# STM32U083 register map
File version: 0.2
CPU: CM0+ r0p1, little endian, MPU, no FPU, 4 interrupt priority bits
Registers are 32-bit, read-write, reset 0x0 unless marked. A register's access mark holds for its fields unless they carry their own. Offsets are from the block's base; [hi:lo] are bit positions.

## DAC — DAC address block description
Base 0x40007400
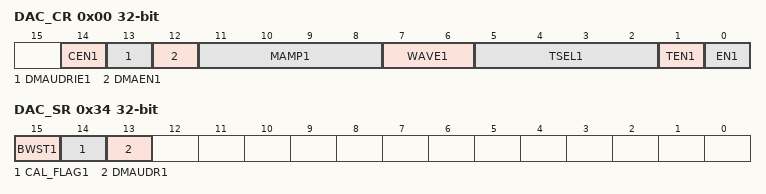
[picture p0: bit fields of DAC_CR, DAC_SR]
0x00 DAC_CR — DAC control register
  [14] CEN1 — DAC channel1 calibration enable This bit is set and cleared by software to enable/disable DAC channel1 calibration, it can be written only if bit EN11=10 into DAC_CR (the calibration mode can be entered/exit only when the DAC channel is disabled) Otherwise, the write operation is ignored.
    0=DAC channel1 in Normal operating mode; 1=DAC channel1 in calibration mode
  [13] DMAUDRIE1 — DAC channel1 DMA Underrun Interrupt enable This bit is set and cleared by software.
    0=DAC channel1 DMA Underrun Interrupt disabled; 1=DAC channel1 DMA Underrun Interrupt enabled
  [12] DMAEN1 — DAC channel1 DMA enable This bit is set and cleared by software.
    0=DAC channel1 DMA mode disabled; 1=DAC channel1 DMA mode enabled
  [11:8] MAMP1 — DAC channel1 mask/amplitude selector
    0=Unmask bit0 of LFSR/ triangle amplitude equal to 1; 1=Unmask bits[1:0] of LFSR/ triangle amplitude equal to 3; 2=Unmask bits[2:0] of LFSR/ triangle amplitude equal to 7; 3=Unmask bits[3:0] of LFSR/ triangle amplitude equal to 15; 4=Unmask bits[4:0] of LFSR/ triangle amplitude equal to 31; 5=Unmask bits[5:0] of LFSR/ triangle amplitude equal to 63; 6=Unmask bits[6:0] of LFSR/ triangle amplitude equal to 127; 7=Unmask bits[7:0] of LFSR/ triangle amplitude equal to 255; 8=Unmask bits[8:0] of LFSR/ triangle amplitude equal to 511; 9=Unmask bits[9:0] of LFSR/ triangle amplitude equal to 1023; 10=Unmask bits[10:0] of LFSR/ triangle amplitude equal to 2047
  [7:6] WAVE1 — DAC channel1 noise/triangle wave generation enable These bits are set and cleared by software. 1x: Triangle wave generation enabled Only used if bit TEN11=11 (DAC channel1 trigger enabled).
    0=wave generation disabled; 1=Noise wave generation enabled
  [5:2] TSEL1 — DAC channel1 trigger selection These bits select the external event used to trigger DAC channel1 ... Refer to the trigger selection tables in Section114.4.2: DAC pins and internal signals for details on trigger configuration and mapping. Note: Only used if bit TEN11=11 (DAC channel1 trigger enabled).
    0=SWTRIG1; 1=dac_ch1_trg1; 2=dac_ch1_trg2; 15=dac_ch1_trg15
  [1] TEN1 — DAC channel1 trigger enable This bit is set and cleared by software to enable/disable DAC channel1 trigger. Note: When software trigger is selected, the transfer from the DAC_DHR1 register to the DAC_DOR1 register takes only one dac_pclk clock cycle.
    0=DAC channel1 trigger disabled and data written into the DAC_DHR1 register are transferred one dac_pclk clock cycle later to the DAC_DOR1 register; 1=DAC channel1 trigger enabled and data from the DAC_DHR1 register are transferred three dac_pclk clock cycles later to the DAC_DOR1 register
  [0] EN1 — DAC channel1 enable This bit is set and cleared by software to enable/disable DAC channel1.
    0=DAC channel1 disabled; 1=DAC channel1 enabled
0x04 DAC_SWTRGR wo — DAC software trigger register
  [0] SWTRIG1 — DAC channel1 software trigger This bit is set by software to trigger the DAC in software trigger mode. Note: This bit is cleared by hardware (one dac_pclk clock cycle later) once the DAC_DHR1 register value has been loaded into the DAC_DOR1 register.
    0=No trigger; 1=Trigger
0x08 DAC_DHR12R1 — DAC channel1 12-bit right-aligned data holding register
  [11:0] DACC1DHR — DAC channel1 12-bit right-aligned data These bits are written by software. They specify 12-bit data for DAC channel1.
0x0C DAC_DHR12L1 — DAC channel1 12-bit left aligned data holding register
  [15:4] DACC1DHR — DAC channel1 12-bit left-aligned data These bits are written by software. They specify 12-bit data for DAC channel1.
0x10 DAC_DHR8R1 — DAC channel1 8-bit right aligned data holding register
  [7:0] DACC1DHR — DAC channel1 8-bit right-aligned data These bits are written by software. They specify 8-bit data for DAC channel1.
0x2C DAC_DOR1 ro — DAC channel1 data output register
  [11:0] DACC1DOR — DAC channel1 data output These bits are read-only, they contain data output for DAC channel1.
0x34 DAC_SR access per field — DAC status register
  [15] BWST1 ro — DAC channel1 busy writing sample time flag This bit is systematically set just after Sample and hold mode enable and is set each time the software writes the register DAC_SHSR1, It is cleared by hardware when the write operation of DAC_SHSR1 is complete. (It takes about 3 LSI periods of synchronization).
    0=There is no write operation of DAC_SHSR1 ongoing: DAC_SHSR1 can be written; 1=There is a write operation of DAC_SHSR1 ongoing: DAC_SHSR1 cannot be written
  [14] CAL_FLAG1 ro — DAC channel1 calibration offset status This bit is set and cleared by hardware
    0=calibration trimming value is lower than the offset correction value; 1=calibration trimming value is equal or greater than the offset correction value
  [13] DMAUDR1 rw — DAC channel1 DMA underrun flag This bit is set by hardware and cleared by software (by writing it to 1).
    0=No DMA underrun error condition occurred for DAC channel1; 1=DMA underrun error condition occurred for DAC channel1 (the currently selected trigger is driving DAC channel1 conversion at a frequency higher than the DMA service capability rate)
0x38 DAC_CCR (reset mask 0xFFFFFF00) — DAC calibration control register
  [4:0] OTRIM1 — DAC channel1 offset trimming value
0x3C DAC_MCR — DAC mode control register
  [2:0] MODE1 — DAC channel1 mode These bits can be written only when the DAC is disabled and not in the calibration mode (when bit EN11=10 and bit CEN11=10 in the DAC_CR register). If EN11=11 or CEN11=11 the write operation is ignored. They can be set and cleared by software to select the DAC channel1 mode: DAC channel1 in Normal mode DAC channel1 in sample & hold mode Note: This register can be modified only when EN11=10.
    0=DAC channel1 is connected to external pin with Buffer enabled; 1=DAC channel1 is connected to external pin and to on chip peripherals with Buffer enabled; 2=DAC channel1 is connected to external pin with Buffer disabled; 3=DAC channel1 is connected to on chip peripherals with Buffer disabled; 4=DAC channel1 is connected to external pin with Buffer enabled; 5=DAC channel1 is connected to external pin and to on chip peripherals with Buffer enabled; 6=DAC channel1 is connected to external pin and to on chip peripherals with Buffer disabled; 7=DAC channel1 is connected to on chip peripherals with Buffer disabled
0x40 DAC_SHSR1 — DAC channel1 sample and hold sample time register
  [9:0] TSAMPLE1 — DAC channel1 sample time (only valid in Sample and hold mode) These bits can be written when the DAC channel1 is disabled or also during normal operation. in the latter case, the write can be done only when BWST1 of DAC_SR register is low, If BWST11=11, the write operation is ignored.
0x48 DAC_SHHR reset 0x10001 — DAC sample and hold time register
  [9:0] THOLD1 — DAC channel1 hold time (only valid in Sample and hold mode) Hold time1=1(THOLD[9:0]) x LSI clock period Note: This register can be modified only when EN11=10.
0x4C DAC_SHRR reset 0x10001 — DAC sample and hold refresh time register
  [7:0] TREFRESH1 — DAC channel1 refresh time (only valid in Sample and hold mode) Refresh time1=1(TREFRESH[7:0]) x LSI clock period Note: This register can be modified only when EN11=10.
